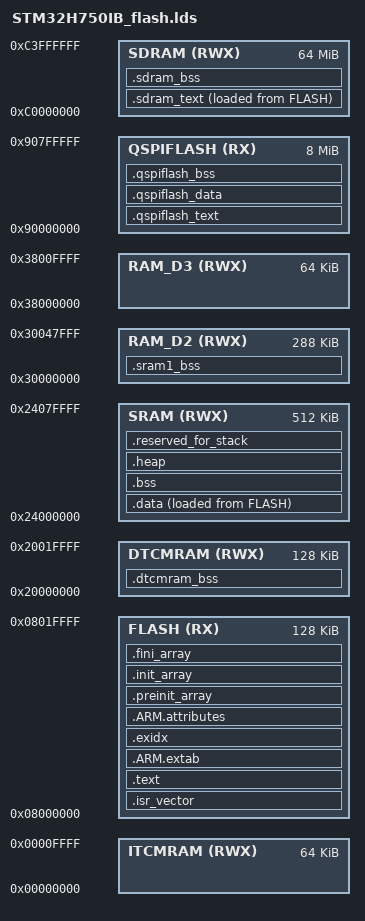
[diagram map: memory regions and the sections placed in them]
/* Generated by LinkerScriptGenerator [http://visualgdb.com/tools/LinkerScriptGenerator]
 * Target: STM32H750IB
 * The file is provided under the BSD license.
 */

ENTRY(Reset_Handler)

MEMORY
{
	FLASH (RX)    : ORIGIN = 0x08000000, LENGTH = 128K
	DTCMRAM (RWX) : ORIGIN = 0x20000000, LENGTH = 128K
	SRAM (RWX)    : ORIGIN = 0x24000000, LENGTH = 512K
	RAM_D2 (RWX)  : ORIGIN = 0x30000000, LENGTH = 288K
	RAM_D3 (RWX)  : ORIGIN = 0x38000000, LENGTH = 64K
	ITCMRAM (RWX) : ORIGIN = 0x00000000, LENGTH = 64K
	SDRAM (RWX)   : ORIGIN = 0xc0000000, LENGTH = 64M
    QSPIFLASH (RX)  : ORIGIN = 0x90000000, LENGTH = 8M
}

_estack = 0x20020000;

SECTIONS
{
	.isr_vector :
	{
		. = ALIGN(4);
		KEEP(*(.isr_vector))
		. = ALIGN(4);
	} > FLASH

	.text :
	{
		. = ALIGN(4);
		_stext = .;

		*(.text)
		*(.text*)
		*(.rodata)
		*(.rodata*)
		*(.glue_7)
		*(.glue_7t)
		KEEP(*(.init))
		KEEP(*(.fini))
		. = ALIGN(4);
		_etext = .;

	} > FLASH

	.ARM.extab :
	{
		. = ALIGN(4);
		*(.ARM.extab)
		*(.gnu.linkonce.armextab.*)
		. = ALIGN(4);
	} > FLASH

	.exidx :
	{
		. = ALIGN(4);
		PROVIDE(__exidx_start = .);
		*(.ARM.exidx*)
		. = ALIGN(4);
		PROVIDE(__exidx_end = .);
	} > FLASH

	.ARM.attributes :
	{
		*(.ARM.attributes)
	} > FLASH

	.preinit_array :
	{
		PROVIDE(__preinit_array_start = .);
		KEEP(*(.preinit_array*))
		PROVIDE(__preinit_array_end = .);
	} > FLASH

	.init_array :
	{
		PROVIDE(__init_array_start = .);
		KEEP(*(SORT(.init_array.*)))
		KEEP(*(.init_array*))
		PROVIDE(__init_array_end = .);
	} > FLASH

	.fini_array :
	{
		PROVIDE(__fini_array_start = .);
		KEEP(*(.fini_array*))
		KEEP(*(SORT(.fini_array.*)))
		PROVIDE(__fini_array_end = .);
	} > FLASH

	.data :
	{
		. = ALIGN(4);
		_sdata = .;

		PROVIDE(__data_start__ = _sdata);
		*(.data)
		*(.data*)
		. = ALIGN(4);
		_edata = .;

		PROVIDE(__data_end__ = _edata);
	} > SRAM AT >FLASH

	_sidata = LOADADDR(.data);

	.bss :
	{
		. = ALIGN(4);
		_sbss = .;

		PROVIDE(__bss_start__ = _sbss);
		*(.bss)
		*(.bss*)
		*(COMMON)
		. = ALIGN(4);
		_ebss = .;

		PROVIDE(__bss_end__ = _ebss);
	} > SRAM

	.dtcmram_bss :
	{
		. = ALIGN(4);
		_sdtcmram_bss = .;

		PROVIDE(__dtcmram_bss_start__ = _sdtcmram_bss);
		*(.dtcmram_bss)
		*(.dtcmram_bss*)
		*(COMMON)
		. = ALIGN(4);
		_edtcmram_bss = .;

		PROVIDE(__dtcmram_bss_end__ = _edtcmram_bss);
	} > DTCMRAM

	.sram1_bss :
	{
		. = ALIGN(4);
		_ssram1_bss = .;

		PROVIDE(__sram1_bss_start__ = _sram1_bss);
		*(.sram1_bss)
		*(.sram1_bss*)
		*(COMMON)
		. = ALIGN(4);
		_esram1_bss = .;

		PROVIDE(__sram1_bss_end__ = _esram1_bss);
	} > RAM_D2

	.sdram_text :
	{
		. = ALIGN(4);
		_ssdram_text = .;

		PROVIDE(__sdram_text_start = _ssdram_text);
		*(.sdram_text)
		*(.sdram_text*)
		. = ALIGN(4);
		_esdram_text = .;

		PROVIDE(__sdram_text_end = _esdram_text);
	} > SDRAM AT >FLASH
	_sisdram_text = LOADADDR(.sdram_text);

	.sdram_bss (NOLOAD) :
	{
		. = ALIGN(4);
		_ssdram_bss = .;

		PROVIDE(__sdram_bss_start = _ssdram_bss);
		*(.sdram_bss)
		*(.sdram_bss*)
		. = ALIGN(4);
		_esdram_bss = .;

		PROVIDE(__sdram_bss_end = _esdram_bss);
	} > SDRAM

	PROVIDE(end = .);

    .qspiflash_text :
	{
		. = ALIGN(4);
		_sqspiflash_text = .;

		PROVIDE(__qspiflash_text_start = _sqspiflash_text);
		*(.qspiflash_text)
		*(.qspiflash_text*)
		. = ALIGN(4);
		_eqspiflash_text = .;

		PROVIDE(__qspiflash_text_end = _eqspiflash_text);
	} > QSPIFLASH

	.qspiflash_data :
	{
		. = ALIGN(4);
		_sqspiflash_data = .;

		PROVIDE(__qspiflash_data_start = _sqspiflash_data);
		*(.qspiflash_data)
		*(.qspiflash_data*)
		. = ALIGN(4);
		_eqspiflash_data = .;

		PROVIDE(__qspiflash_data_end = _eqspiflash_data);
	} > QSPIFLASH

	.qspiflash_bss (NOLOAD) :
	{
		. = ALIGN(4);
		_sqspiflash_bss = .;

		PROVIDE(__qspiflash_bss_start = _sqspiflash_bss);
		*(.qspiflash_bss)
		*(.qspiflash_bss*)
		. = ALIGN(4);
		_eqspiflash_bss = .;

		PROVIDE(__qspiflash_bss_end = _eqspiflash_bss);
	} > QSPIFLASH

	.heap (NOLOAD) :
	{
		. = ALIGN(4);
		PROVIDE(__heap_start__ = .);
		KEEP(*(.heap))
		. = ALIGN(4);
		PROVIDE(__heap_end__ = .);
	} > SRAM

	.reserved_for_stack (NOLOAD) :
	{
		. = ALIGN(4);
		PROVIDE(__reserved_for_stack_start__ = .);
		KEEP(*(.reserved_for_stack))
		. = ALIGN(4);
		PROVIDE(__reserved_for_stack_end__ = .);
	} > SRAM

}

